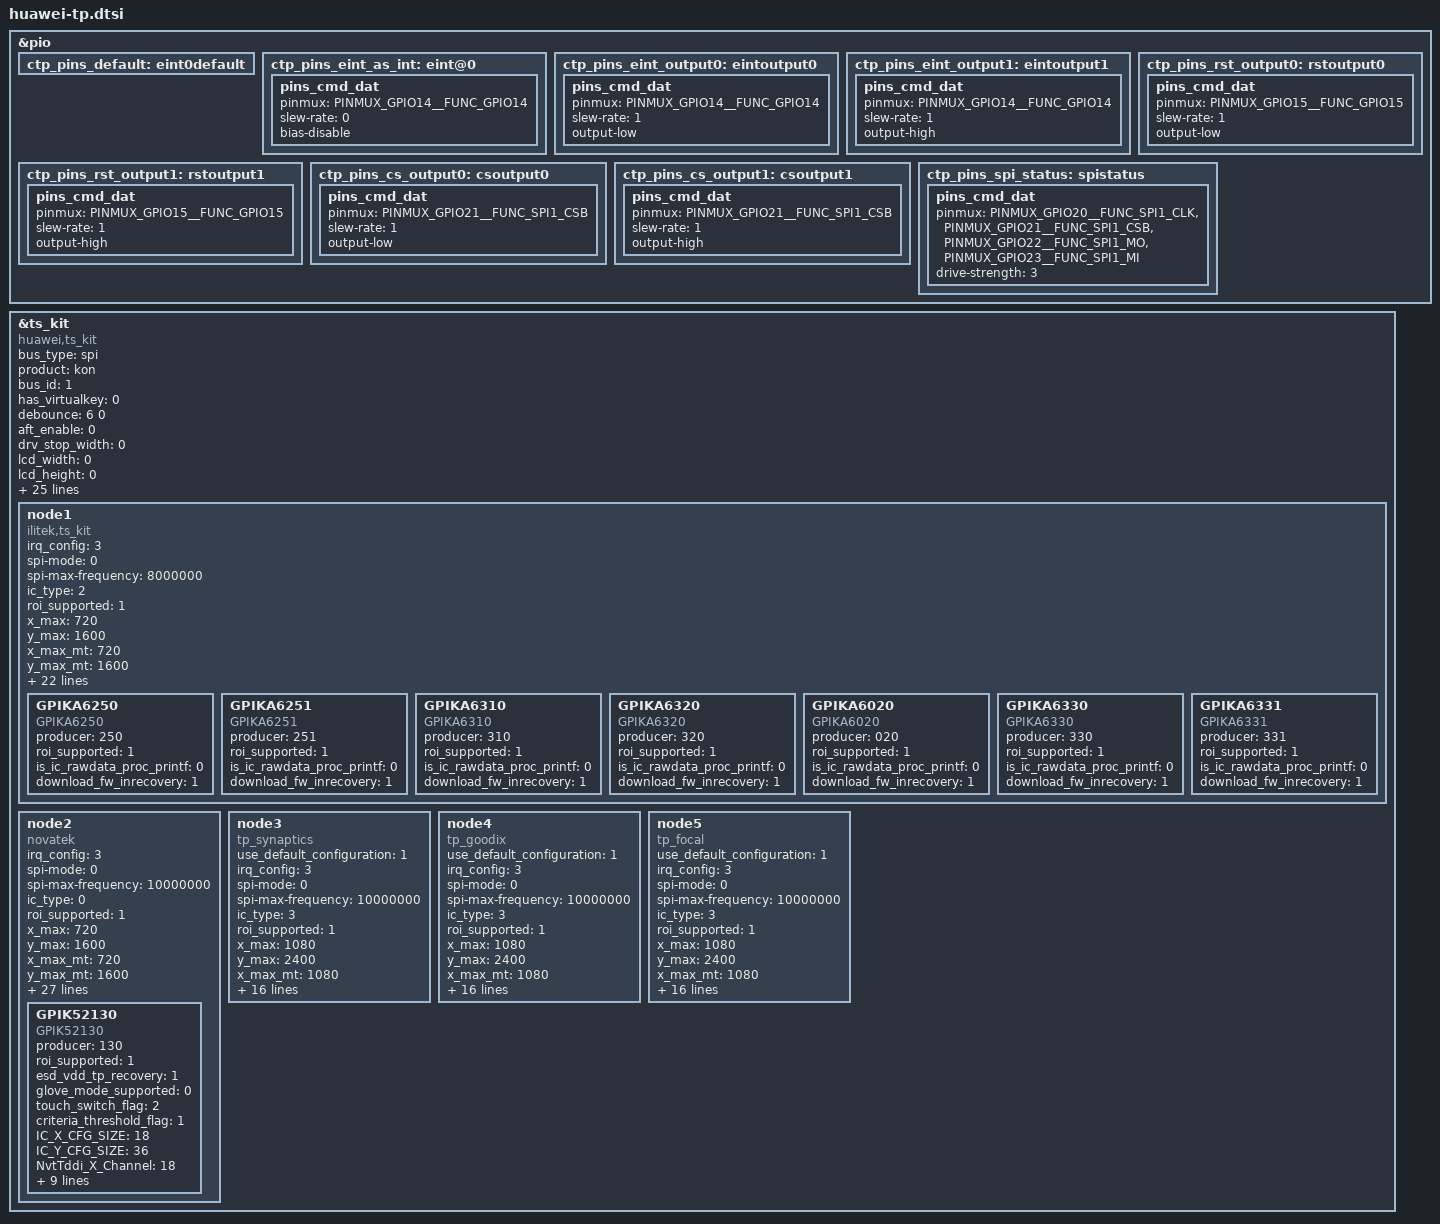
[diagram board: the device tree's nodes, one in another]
&pio {
	ctp_pins_default: eint0default {
	};
	ctp_pins_eint_as_int: eint@0 {
		pins_cmd_dat {
			pinmux = <PINMUX_GPIO14__FUNC_GPIO14>;
			slew-rate = <0>;
			bias-disable;
		};
	};
	ctp_pins_eint_output0: eintoutput0 {
		pins_cmd_dat {
			pinmux = <PINMUX_GPIO14__FUNC_GPIO14>;
			slew-rate = <1>;
			output-low;
		};
	};
	ctp_pins_eint_output1: eintoutput1 {
		pins_cmd_dat {
			pinmux = <PINMUX_GPIO14__FUNC_GPIO14>;
			slew-rate = <1>;
			output-high;
		};
	};
	ctp_pins_rst_output0: rstoutput0 {
		pins_cmd_dat {
			pinmux = <PINMUX_GPIO15__FUNC_GPIO15>;
			slew-rate = <1>;
			output-low;
		};
	};
	ctp_pins_rst_output1: rstoutput1 {
		pins_cmd_dat {
			pinmux = <PINMUX_GPIO15__FUNC_GPIO15>;
			slew-rate = <1>;
			output-high;
		};
	};

	ctp_pins_cs_output0: csoutput0 {
		pins_cmd_dat {
			pinmux = <PINMUX_GPIO21__FUNC_SPI1_CSB>;
			slew-rate = <1>;
			output-low;
		};
	};
	ctp_pins_cs_output1: csoutput1 {
		pins_cmd_dat {
			pinmux = <PINMUX_GPIO21__FUNC_SPI1_CSB>;
			slew-rate = <1>;
			output-high;
		};
	};
	ctp_pins_spi_status: spistatus {
		pins_cmd_dat {
			pinmux = <PINMUX_GPIO20__FUNC_SPI1_CLK>,
				 <PINMUX_GPIO21__FUNC_SPI1_CSB>,
				 <PINMUX_GPIO22__FUNC_SPI1_MO>,
				 <PINMUX_GPIO23__FUNC_SPI1_MI>;
			drive-strength = <3>;
		};
	};
};
/*ts kit*/
&ts_kit {
	status = "okay";
	compatible = "huawei,ts_kit";	/* Do not change value*/
	bus_type = "spi";
	product = "kon";
	bus_id = <1>;
	has_virtualkey = <0>;
	debounce = <6 0>;
	aft_enable = <0>;	/* aft algo switch. 1 - enabel, 0 - disable*/
	drv_stop_width = <0>;	/* always 0, can not config */
	lcd_width = <0>;	/* always 0, can not config */
	lcd_height = <0>;	/* always 0, can not config */
	need_i2c_hwlock = <0>;	/* for i2c both used by ap and sensorhub */
	register_charger_notifier = <0>;
	hide_plain_id = <1>;
	interrupt-parent = <&pio>;
	interrupts = <14 2 0 0>;
	cs_gpio = <&pio 21 0>;
	pl022,com-mode = <1>;
	pl022,interface = <0>;
	pl022,rx-level-trig = <3>;
	pl022,tx-level-trig = <3>;
	pl022,ctrl-len = <7>;
	pl022,wait-state = <0>;
	pl022,duplex = <0>;
	pl022,slave-tx-disable = <0>;
	spi-max-frequency = <8000000>;
	spi-mode = <0>;
	cs_reset_low_delay = <10>;
	cs_reset_high_delay = <200>;
	mtk_spi_mlsb_config = <1>;
	mtk_rx_mlsb = <1>;
	mtk_tx_mlsb = <1>;
	mtk_cs_pol = <0>;
	mtk_sample_sel = <0>;
	mtk_cs_setuptime = <28>;
	recovery_update_fw = <1>;
	node1 {
		compatible = "ilitek,ts_kit";
		irq_config = <3>;
		spi-mode = <0>;
		spi-max-frequency = <8000000>;
		ic_type = <2>;
		roi_supported = <1>;
		x_max = <720>;
		y_max = <1600>;
		x_max_mt = <720>;
		y_max_mt = <1600>;
		/* pinctl config part */
		pinctrl-names = "default", "idle", "state_eint_as_int", "state_eint_output0",
			"state_eint_output1","state_rst_output0","state_rst_output1",
			"state_cs_output0", "state_cs_output1";
		pinctrl-0 = <&ctp_pins_rst_output1 &ctp_pins_cs_output1>;
		pinctrl-1 = <&ctp_pins_rst_output0 &ctp_pins_cs_output0>;
		pinctrl-2 = <&ctp_pins_eint_as_int>;
		pinctrl-3 = <&ctp_pins_eint_output0>;
		pinctrl-4 = <&ctp_pins_eint_output1>;
		pinctrl-5 = <&ctp_pins_rst_output0>;
		pinctrl-6 = <&ctp_pins_rst_output1>;
		pinctrl-7 = <&ctp_pins_cs_output0>;
		pinctrl-8 = <&ctp_pins_cs_output1>;
		algo_id = <1>;
		gesture_supported = <1>;
		download_fw_inrecovery = <1>;
		use_lcdkit_power_notify = <1>;
		hide_fw_name = <1>;
		touch_switch_flag = <4>;
		project_id_length_control = <9>;
		only_open_once_captest_threshold = <0>;
		tp_test_type = "Normalize_type:judge_last_result";
		rawdata_get_timeout = <10>;
		mtk_irq_gpio = <&pio 14 0>;
		GPIKA6250 {
			producer = "250";
			compatible = "GPIKA6250";
			roi_supported = <1>;
			is_ic_rawdata_proc_printf = <0>;
			download_fw_inrecovery = <1>;
		};
		GPIKA6251 {
			producer = "251";
			compatible = "GPIKA6251";
			roi_supported = <1>;
			is_ic_rawdata_proc_printf = <0>;
			download_fw_inrecovery = <1>;
		};
		GPIKA6310 {
			producer = "310";
			compatible = "GPIKA6310";
			roi_supported = <1>;
			is_ic_rawdata_proc_printf = <0>;
			download_fw_inrecovery = <1>;
		};
		GPIKA6320 {
			producer = "320";
			compatible = "GPIKA6320";
			roi_supported = <1>;
			is_ic_rawdata_proc_printf = <0>;
			download_fw_inrecovery = <1>;
		};
		GPIKA6020 {
			producer = "020";
			compatible = "GPIKA6020";
			roi_supported = <1>;
			is_ic_rawdata_proc_printf = <0>;
			download_fw_inrecovery = <1>;
		};
		GPIKA6330 {
			producer = "330";
			compatible = "GPIKA6330";
			roi_supported = <1>;
			is_ic_rawdata_proc_printf = <0>;
			download_fw_inrecovery = <1>;
		};
		GPIKA6331 {
			producer = "331";
			compatible = "GPIKA6331";
			roi_supported = <1>;
			is_ic_rawdata_proc_printf = <0>;
			download_fw_inrecovery = <1>;
		};
	};
	node2 {
		compatible = "novatek";
		/* ts chip common config, parsed by paltform */
		/* hardware config part */
		irq_config = <3>;/* 0 - LOW LEVEL  1 - HIGH LEVEL  2 - RAISE EDGE  3 - FALL EDGE*/
		spi-mode = <0>;
		spi-max-frequency = <10000000>;
		ic_type = <0>;
		roi_supported = <1>;
		x_max = <720>;
		y_max = <1600>;
		x_max_mt = <720>;
		y_max_mt = <1600>;
		tp_test_type = "Normalize_type:judge_last_result";

		/* pinctl config part */
		pinctrl-names = "default", "idle", "state_eint_as_int", "state_eint_output0",
			"state_eint_output1","state_rst_output0","state_rst_output1",
			"state_cs_output0", "state_cs_output1";
		pinctrl-0 = <&ctp_pins_rst_output1 &ctp_pins_cs_output1>;
		pinctrl-1 = <&ctp_pins_rst_output0 &ctp_pins_cs_output0>;
		pinctrl-2 = <&ctp_pins_eint_as_int>;
		pinctrl-3 = <&ctp_pins_eint_output0>;
		pinctrl-4 = <&ctp_pins_eint_output1>;
		pinctrl-5 = <&ctp_pins_rst_output0>;
		pinctrl-6 = <&ctp_pins_rst_output1>;
		pinctrl-7 = <&ctp_pins_cs_output0>;
		pinctrl-8 = <&ctp_pins_cs_output1>;

		algo_id = <1>;
		noise_test_frame = <30>;
		open_test_by_fw = <1>;
		support_aft = <0>;
		glove_mode_supported = <0>;
		default_projectid = "GPIK52130";
		use_dma_download_firmware = <0>;
		use_pinctrl=<1>;
		charger_supported = <1>;
		tp_status_report_support = <0>;
		is_ic_rawdata_proc_printf = <0>;
		gesture_supported = <1>;
		gesture_module = <1>;
		power_sleep_mode = <1>;
		scene_type_mode = <2>; /* 0-normal, 1-power genius, 2-iTouch */
		GPIK52130 {
			producer = "130";
			compatible = "GPIK52130";
			roi_supported = <1>;
			esd_vdd_tp_recovery = <1>;
			glove_mode_supported = <0>;
			touch_switch_flag = <2>;
			criteria_threshold_flag = <1>;
			IC_X_CFG_SIZE = <18>;
			IC_Y_CFG_SIZE = <36>;
			NvtTddi_X_Channel = <18>;
			NvtTddi_Y_Channel = <36>;
			huawei,csvfile_use_system = <2>;
			huawei,test_capacitance_via_csvfile = <1>;
			mADCOper_Cnt = <2>;
			NVT_TDDI_AIN_X = <0 1 2 3 4 5 6 7 8 9 10 11 12 13 14 15 16 17>;
			NVT_TDDI_AIN_Y = <0 1 2 3 4 5 6 7 8 9 10 11 12 13 14 15 16 17 18 19 20 21 22 23 24 25 26 27 28 29 30 31 32 33 34 35>;
			hide_fw_name = <1>;
		};
	};
	node3 {
		use_default_configuration = <1>;
		compatible = "tp_synaptics";
		/* ts chip common config, parsed by paltform */
		/* hardware config part */
		irq_config = <3>;/* 0 - LOW LEVEL  1 - HIGH LEVEL  2 - RAISE EDGE  3 - FALL EDGE*/
		spi-mode = <0>;
		spi-max-frequency = <10000000>;
		ic_type = <3>;
		roi_supported = <1>;
		x_max = <1080>;
		y_max = <2400>;
		x_max_mt = <1080>;
		y_max_mt = <2400>;
		tp_test_type = "Normalize_type:judge_last_result";
		algo_id = <1>;
		noise_test_frame = <30>;
		open_test_by_fw = <1>;
		support_aft = <0>;
		glove_mode_supported = <0>;
		use_dma_download_firmware = <0>;
		use_pinctrl=<1>;
		charger_supported = <1>;
		tp_status_report_support = <0>;
		is_ic_rawdata_proc_printf = <0>;
		gesture_supported = <1>;
		gesture_module = <1>;
		power_sleep_mode = <1>;
		scene_type_mode = <2>; /* 0-normal, 1-power genius, 2-iTouch */
	};
	node4 {
		use_default_configuration = <1>;
		compatible = "tp_goodix";
		/* ts chip common config, parsed by paltform */
		/* hardware config part */
		irq_config = <3>;/* 0 - LOW LEVEL  1 - HIGH LEVEL  2 - RAISE EDGE  3 - FALL EDGE*/
		spi-mode = <0>;
		spi-max-frequency = <10000000>;
		ic_type = <3>;
		roi_supported = <1>;
		x_max = <1080>;
		y_max = <2400>;
		x_max_mt = <1080>;
		y_max_mt = <2400>;
		tp_test_type = "Normalize_type:judge_last_result";
		algo_id = <1>;
		noise_test_frame = <30>;
		open_test_by_fw = <1>;
		support_aft = <0>;
		glove_mode_supported = <0>;
		use_dma_download_firmware = <0>;
		use_pinctrl=<1>;
		charger_supported = <1>;
		tp_status_report_support = <0>;
		is_ic_rawdata_proc_printf = <0>;
		gesture_supported = <1>;
		gesture_module = <1>;
		power_sleep_mode = <1>;
		scene_type_mode = <2>; /* 0-normal, 1-power genius, 2-iTouch */
	};
	node5 {
		use_default_configuration = <1>;
		compatible = "tp_focal";
		/* ts chip common config, parsed by paltform */
		/* hardware config part */
		irq_config = <3>;/* 0 - LOW LEVEL  1 - HIGH LEVEL  2 - RAISE EDGE  3 - FALL EDGE*/
		spi-mode = <0>;
		spi-max-frequency = <10000000>;
		ic_type = <3>;
		roi_supported = <1>;
		x_max = <1080>;
		y_max = <2400>;
		x_max_mt = <1080>;
		y_max_mt = <2400>;
		tp_test_type = "Normalize_type:judge_last_result";
		algo_id = <1>;
		noise_test_frame = <30>;
		open_test_by_fw = <1>;
		support_aft = <0>;
		glove_mode_supported = <0>;
		use_dma_download_firmware = <0>;
		use_pinctrl=<1>;
		charger_supported = <1>;
		tp_status_report_support = <0>;
		is_ic_rawdata_proc_printf = <0>;
		gesture_supported = <1>;
		gesture_module = <1>;
		power_sleep_mode = <1>;
		scene_type_mode = <2>; /* 0-normal, 1-power genius, 2-iTouch */
	};
};
